# RasbperryPi register map
File version: 1
Registers are 32-bit, read-write, reset 0x0 unless marked. A register's access mark holds for its fields unless they carry their own. Offsets are from the block's base; [hi:lo] are bit positions; {n}, {i} and the like mark numbered series; 'fields as' and 'values as' point back to an identical list.

## MS — Derived from multicore_sync.h apb_id: 0x4D554C54
Base 0x7E000000
{0x0+4i} SEMA_{i} 1-bit (i=0..31)
  [0] MASK
0x80 STATUS ro
0x84 IREQ_0
0x88 IREQ_1
0x90 ICSET_0 1-bit
  [0] ICSET_0
0x94 ICSET_1 1-bit
  [0] ICSET_1
0x98 ICCLR_0 1-bit
  [0] ICCLR_0
0x9C ICCLR_1 1-bit
  [0] ICCLR_1
{0xA0+4i} MBOX_{i} (i=0..7)
  [31:0] MBOX
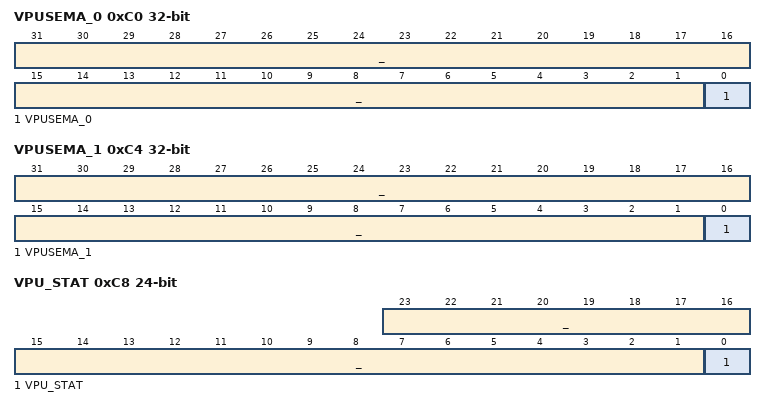
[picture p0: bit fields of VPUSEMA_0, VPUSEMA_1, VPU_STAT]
0xC0 VPUSEMA_0 reset not defined
  [31:1] _, [0] VPUSEMA_0
0xC4 VPUSEMA_1 reset not defined
  [31:1] _, [0] VPUSEMA_1
0xC8 VPU_STAT 24-bit ro reset not defined
  [23:1] _, [0] VPU_STAT

## NU — Derived from nexus_uba.h
Base 0x7E008000
0x00 HOSTIO_OF
  [31:0] data

## OTP — Derived from otp.h apb_id: 0x206F7470
Base 0x7E20F000
0x00 BOOTMODE_REG reset not defined
  [31:0] data
0x04 CONFIG_REG 3-bit reset not defined
  [2:0] data
0x08 CTRL_LO_REG reset not defined
  [31:0] data
0x0C CTRL_HI_REG 16-bit reset not defined
  [15:0] data
0x10 STATUS_REG ro reset not defined
  [31:0] data
0x14 BITSEL_REG 5-bit reset not defined
  [4:0] data
0x18 DATA_REG 5-bit reset not defined
  [4:0] data
0x1C ADDR_REG 5-bit reset not defined
  [4:0] data
0x20 WRITE_DATA_READ_REG reset not defined
  [31:0] data
0x24 INIT_STATUS_REG reset not defined
  [31:0] data

## PCM — Derived from pcm.h
Base 0x7E203000
0x00 CS_A 26-bit
  [25] STBY, [24] SYNC, [23] RXSEX, [22] RXF, [21] TXE, [20] RXD, [19] TXD, [18] RXR, [17] TXW, [16] RXERR, [15] TXERR, [14] RXSYNC, [13] TXSYNC, [12:10] _, [9] DMAEN, [8:7] RXTHR, [6:5] TXTHR, [4] RXCLR, [3] TXCLR, [2] TXON, [1] RXON, [0] EN
0x04 FIFO_A reset not defined
  [31:0] data
0x08 MODE_A 29-bit
  [28] CLK_DIS, [27] PDMN, [26] PDME, [25] FRXP, [24] FTXP, [23] CLKM, [22] CLKI, [21] FSM, [20] FSI, [19:10] FLEN, [9:0] FSLEN
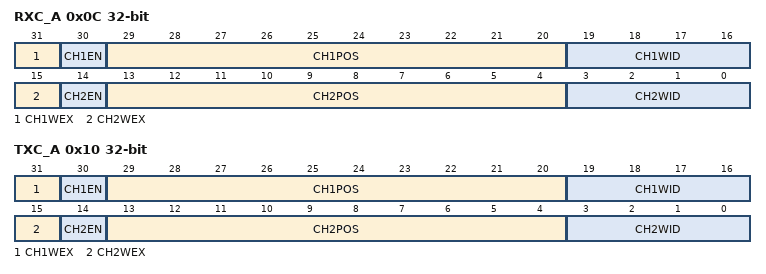
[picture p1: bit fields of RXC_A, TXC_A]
0x0C RXC_A
  [31] CH1WEX, [30] CH1EN, [29:20] CH1POS, [19:16] CH1WID, [15] CH2WEX, [14] CH2EN, [13:4] CH2POS, [3:0] CH2WID
0x10 TXC_A
  fields as RXC_A
0x14 DREQ_A 31-bit reset 0x20
  [30:24] TX_PANIC, [23] _, [22:16] RX_PANIC, [15] _, [14:8] TX, [7] _, [6:0] RX
0x18 INTEN_A 4-bit
  [3] RXERR, [2] TXERR, [1] RXR, [0] TXW
0x1C INTSTC_A 4-bit
  [3] RXERR, [2] TXERR, [1] RXR, [0] TXW
0x20 GRAY 22-bit
  [21:16] RXFIFOLEVEL, [15:10] FLUSHED, [9:4] RXLEVEL, [3] _, [2] FLUSH, [1] CLR, [0] EN

## PRM — Derived from perfmon.h
Base 0x7E20D000
0x00 CS reset not defined
  [31:0] data
0x04 CV reset not defined
  [31:0] data
0x08 SCC reset not defined
  [31:0] data

## PIARBCTL — Derived from peri_image_arb_ctrl.h
Base 0x7E80A000
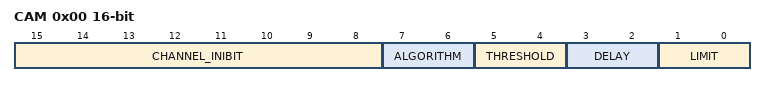
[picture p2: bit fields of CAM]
0x00 CAM 16-bit
  [15:8] CHANNEL_INIBIT, [7:6] ALGORITHM, [5:4] THRESHOLD, [3:2] DELAY, [1:0] LIMIT

## PIXELVALVE0 — Derived from pixel_valve0.h apb_id: 0x70697876
Base 0x7E206000
Same registers: PIXELVALVE1 0x7E207000, PIXELVALVE2 0x7E807000
0x00 C 24-bit reset not defined
  [23:0] data
0x04 VC 23-bit reset not defined
  [22:0] data
0x08 VSYNCD_EVEN 17-bit reset not defined
  [16:0] data
0x0C HORZA reset not defined
  [31:0] data
0x10 HORZB reset not defined
  [31:0] data
0x14 VERTA reset not defined
  [31:0] data
0x18 VERTB reset not defined
  [31:0] data
0x1C VERTA_EVEN reset not defined
  [31:0] data
0x20 VERTB_EVEN reset not defined
  [31:0] data
0x24 INTEN 10-bit reset not defined
  [9:0] data
0x28 INTSTAT 10-bit reset not defined
  [9:0] data
0x2C STAT 10-bit reset not defined
  [9:0] data
0x30 DSI_HACT_ACT 16-bit reset not defined
  [15:0] data

## PWM — Derived from pwm.h apb_id: 0x70776D30
Base 0x7E20C000
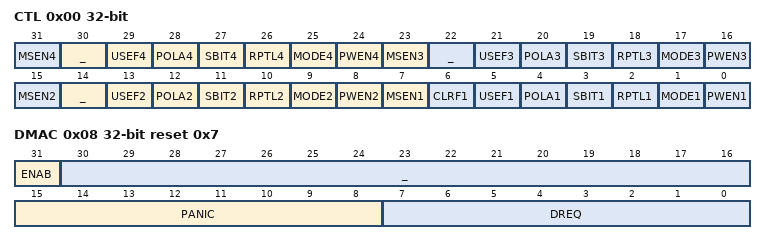
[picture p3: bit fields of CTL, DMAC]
0x00 CTL
  [8n-1] MSEN{n} (n=1..4), [30] _, [8n-3] USEF{n} (n=1..4), [8n-4] POLA{n} (n=1..4), [8n-5] SBIT{n} (n=1..4), [8n-6] RPTL{n} (n=1..4), [8n-7] MODE{n} (n=1..4), [8n-8] PWEN{n} (n=1..4), [22] _, [14] _, [6] CLRF1
0x04 STA 13-bit
  [n+8] STA{n} (n=1..4), [8] BERR, [n+3] GAPO{n} (n=1..4), [3] RERR1, [2] WERR1, [1] EMPT1, [0] FULL1
0x08 DMAC reset 0x7
  [31] ENAB, [30:16] _, [15:8] PANIC, [7:0] DREQ
0x10 RNG1 reset 0x20
  [31:0] data
0x14 DAT1
  [31:0] data
0x18 FIF1
  [31:0] data
0x20 RNG2 reset 0x20
  [31:0] data
0x24 DAT2
  [31:0] data
0x30 RNG3 size not given reset 0x20
0x34 DAT3 size not given
0x40 RNG4 size not given reset 0x20
0x44 DAT4 size not given
